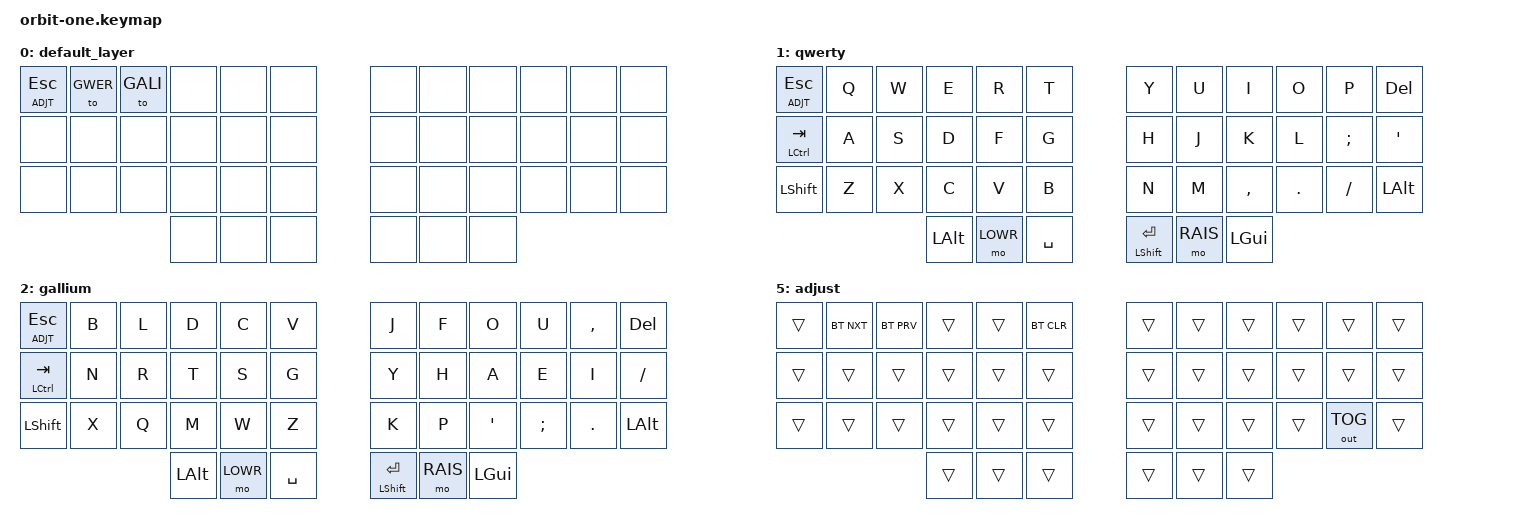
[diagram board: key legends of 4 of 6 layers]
/*
 * Copyright (c) 2021-2025 The ZMK Contributors
 *
 * SPDX-License-Identifier: MIT
 */

#include <behaviors.dtsi>
#include <dt-bindings/zmk/keys.h>
#include <dt-bindings/zmk/bt.h>
#include <dt-bindings/zmk/outputs.h>

#define QWER 2
#define GALI 3
#define LOWR 4
#define RAIS 5
#define ADJT 6

/ {
  behaviors {
      left_rot: sensor_rotate_kp {
          compatible = "zmk,behavior-sensor-rotate-var";
          #sensor-binding-cells = <1>;
          bindings = <&kp>, <&kp>;
      };

      right_rot: sensor_rotate_kp {
          compatible = "zmk,behavior-sensor-rotate-var";
          #sensor-binding-cells = <2>;
          bindings = <&kp>, <&kp>;
      };
  };
  
  keymap {
    compatible = "zmk,keymap";

    default_layer {
      bindings = <
  &lt ADJT ESC  &to GWER &to GALI &none     &none    &none                     &none    &none    &none     &none   &none    &none
  &none         &none    &none    &none     &none    &none                     &none    &none    &none     &none   &none    &none
  &none         &none    &none    &none     &none    &none                     &none    &none    &none     &none   &none    &none
                                  &none     &none    &none                     &none    &none    &none
      >;

        sensor-bindings = <&left_rot DOWN UP>, <&right_rot RIGHT LEFT>;
    };

    qwerty {
      bindings = <
  &lt ADJT ESC  &kp Q &kp W &kp E     &kp R    &kp T                          &kp Y     &kp U    &kp I     &kp O   &kp P    &kp DEL
  &mt LCTRL TAB &kp A &kp S &kp D     &kp F    &kp G                          &kp H     &kp J    &kp K     &kp L   &kp SEMI &kp SQT
      &kp LSHFT &kp Z &kp X &kp C     &kp V    &kp B                          &kp N     &kp M    &kp COMMA &kp DOT &kp FSLH &kp LALT
                             &kp LALT &mo LOWR &kp SPACE                &mt LSHFT ENTER &mo RAIS &kp LGUI
      >;
      sensor-bindings = <&left_rot DOWN UP>, <&right_rot RIGHT LEFT>;
    };

    gallium {
      bindings = <
  &lt ADJT ESC  &kp B &kp L &kp D     &kp C    &kp V                          &kp J     &kp F    &kp O     &kp U    &kp COMMA &kp DEL
  &mt LCTRL TAB &kp N &kp R &kp T     &kp S    &kp G                          &kp Y     &kp H    &kp A     &kp E    &kp I     &kp FSLH
      &kp LSHFT &kp X &kp Q &kp M     &kp W    &kp Z                          &kp K     &kp P    &kp SQT   &kp SEMI &kp DOT   &kp LALT
                             &kp LALT &mo LOWR &kp SPACE                &mt LSHFT ENTER &mo RAIS &kp LGUI
      >;

          sensor-bindings = <&left_rot DOWN UP>, <&right_rot RIGHT LEFT>;
    };

    lower {
      bindings = <
  &kp GRAVE &kp N1    &kp N2   &kp N3   &kp N4   &kp N5           &kp N6   &kp N7   &kp N8 &kp N9    &kp N0  &kp BSPC
  &trans    &kp LCTRL &kp LSFT &kp LALT &kp LGUI &trans           &kp LEFT &kp DOWN &kp UP &kp RIGHT &trans  &trans
  &trans    &kp F1    &kp F2   &kp F3   &kp F4   &kp F5           &kp F6   &kp F7   &kp F8 &kp F9    &kp F10
                               &trans   &trans   &trans           &trans   &trans   &trans
      >;

          sensor-bindings = <&left_rot DOWN UP>, <&right_rot END HOME>;
    };
    raise {
      bindings = <
  &kp TILDE &kp EXCL &kp AT   &kp HASH  &kp DOLLAR &kp PERCENT    &kp CARET  &kp AMPS  &kp ASTRK &kp LPRN  &kp RPRN &kp BSPC
  &trans    &kp LBKT &kp LT   &kp FSLH  &kp GT     &kp RBKT       &trans     &kp MINUS &kp EQUAL &kp GRAVE &kp PIPE &trans
  &trans    &trans   &kp LBRC &kp QMARK &kp RBRC   &trans         &trans     &kp UNDER &kp PLUS  &kp TILDE &kp BSLH
                                 &trans &trans     &trans         &trans     &trans    &trans
      >;

          sensor-bindings = <&left_rot PG_DN PG_UP>, <&right_rot RIGHT LEFT>;
    };

    adjust {
      bindings = <
  &trans &bt BT_NXT &bt BT_PRV &trans       &trans &bt BT_CLR              &trans &trans &trans &trans &trans &trans
  &trans &trans     &trans     &trans       &trans &trans                  &trans &trans &trans &trans &trans &trans
         &trans     &trans     &trans       &trans &trans                  &trans &trans &trans &trans &trans
                               &out OUT_TOG &trans &trans &trans    &trans &trans &trans &trans
      >;
    };
  };
};
